# GD32C231 register map
File version: 1.0
CPU: CM23 r0p0, little endian, MPU, FPU, 4 interrupt priority bits
Registers are 32-bit, read-write, reset 0x0 unless marked. A register's access mark holds for its fields unless they carry their own. Offsets are from the block's base; [hi:lo] are bit positions.

## TIMER15 — General-level4-timers
Base 0x40014400
Same registers: TIMER16 0x40014800
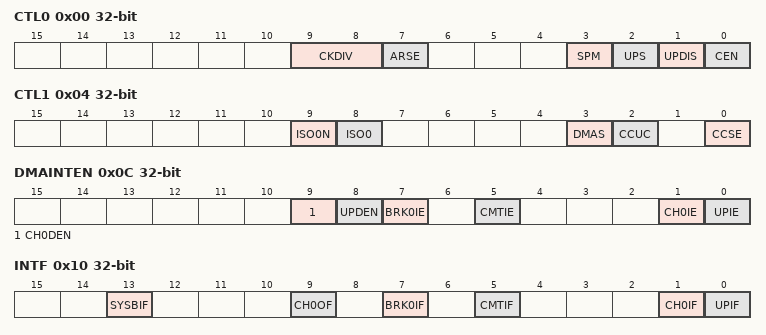
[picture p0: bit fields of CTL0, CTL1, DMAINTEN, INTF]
0x00 CTL0 — Control register 0
  [9:8] CKDIV — Clock division
  [7] ARSE — Auto-reload shadow enable
  [3] SPM — Single pulse mode.
  [2] UPS — Update source
  [1] UPDIS — Update disable.
  [0] CEN — Counter enable
0x04 CTL1 — Control register 1
  [9] ISO0N — Idle state of channel 0 complementary output
  [8] ISO0 — Idle state of channel 0 output
  [3] DMAS — DMA request source selection
  [2] CCUC — Commutation control shadow register update control
  [0] CCSE — Commutation control shadow enable
0x0C DMAINTEN — DMA and interrupt enable register
  [9] CH0DEN — Channel 0 capture/compare DMA request enable
  [8] UPDEN — Update DMA request enable
  [7] BRK0IE — Break interrupt 0 enable
  [5] CMTIE — Commutation interrupt enable
  [1] CH0IE — Channel 0 capture/compare interrupt enable
  [0] UPIE — Update interrupt enable
0x10 INTF — Interrupt flag register
  [13] SYSBIF — System source break interrupt flag
  [9] CH0OF — Channel 0 over capture flag
  [7] BRK0IF — Break 0 interrupt flag
  [5] CMTIF — Channel commutation interrupt flag
  [1] CH0IF — Channel 0 capture/compare interrupt flag
  [0] UPIF — Update interrupt flag
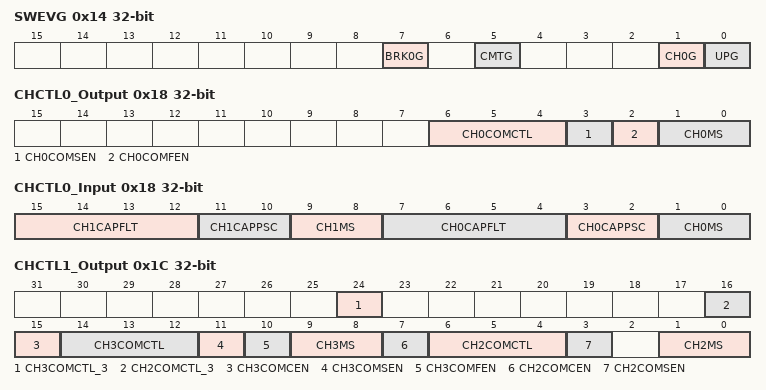
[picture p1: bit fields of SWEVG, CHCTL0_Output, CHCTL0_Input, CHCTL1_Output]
0x14 SWEVG wo — Software event generation register
  [7] BRK0G — Break 0 event generation
  [5] CMTG — Channel commutation event generation
  [1] CH0G — Channel 0 capture or compare event generation
  [0] UPG — Update event generation
0x18 CHCTL0_Output — channel control register 0 (output mode)
  [6:4] CH0COMCTL — Channel 0 compare output control
  [3] CH0COMSEN — Channel 0 compare output shadow enable
  [2] CH0COMFEN — Channel 0 output compare fast enable
  [1:0] CH0MS — Channel 0 I/O mode selection
0x18 CHCTL0_Input (alternate view of CHCTL0_Output) — channel control register 0 (input mode)
  [15:12] CH1CAPFLT — Channel 1 input capture filter control
  [11:10] CH1CAPPSC — Channel 1 input capture prescaler
  [9:8] CH1MS — Channel 1 mode selection
  [7:4] CH0CAPFLT — Channel 0 input capture filter control
  [3:2] CH0CAPPSC — Channel 0 input capture prescaler
  [1:0] CH0MS — Channel 0 mode selection
0x1C CHCTL1_Output — channel control register 1 (output mode)
  [24] CH3COMCTL_3 — Channel 3 compare output control
  [16] CH2COMCTL_3 — Channel 2 compare output control
  [15] CH3COMCEN — Channel 3 output compare clear enable
  [14:12] CH3COMCTL — Channel 3 compare output control
  [11] CH3COMSEN — Channel 3 output compare shadow enable
  [10] CH3COMFEN — Channel 3 output compare fast enable
  [9:8] CH3MS — Channel 3 mode selection
  [7] CH2COMCEN — Channel 2 output compare clear enable
  [6:4] CH2COMCTL — Channel 2 compare output control
  [3] CH2COMSEN — Channel 2 compare output shadow enable
  [1:0] CH2MS — Channel 2 I/O mode selection
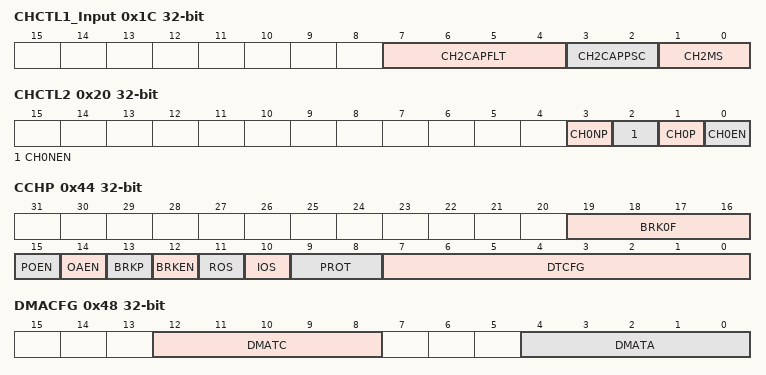
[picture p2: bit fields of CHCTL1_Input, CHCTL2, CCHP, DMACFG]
0x1C CHCTL1_Input (alternate view of CHCTL1_Output) — channel control register 1 (input mode)
  [7:4] CH2CAPFLT — Channel 2 input capture filter control
  [3:2] CH2CAPPSC — Channel 2 input capture prescaler
  [1:0] CH2MS — Channel 2 mode selection
0x20 CHCTL2 — Channel control register 2
  [3] CH0NP — Channel 0 complementary output polarity
  [2] CH0NEN — Channel 0 complementary output enable
  [1] CH0P — Channel 0 capture/compare function polarity
  [0] CH0EN — Channel 0 capture/compare function enable
0x24 CNT — Counter register
  [15:0] CNT — This bit-filed indicates the current counter value. Writing to this bit-filed can change the value of the counter.
0x28 PSC — Prescaler register
  [15:0] PSC — Prescaler value of the counter clock
0x2C CAR — Counter auto reload register
  [15:0] CARL — Counter auto reload value
0x30 CREP — Counter repetition register
  [7:0] CREP — Counter repetition value
0x34 CH0CV — Channel 0 capture/compare value register
  [15:0] CH0VAL — Capture or compare value of channel0
0x44 CCHP — Complementary channel protection register
  [19:16] BRK0F — BREAK0 input signal filter
  [15] POEN — Primary output enable
  [14] OAEN — Output automatic enable
  [13] BRKP — Break polarity
  [12] BRKEN — Break enable
  [11] ROS — Run mode 'off-state' enable
  [10] IOS — Idle mode 'off-state' enable
  [9:8] PROT — Complementary register protect control
  [7:0] DTCFG — Dead time configure
0x48 DMACFG — DMA configuration register
  [12:8] DMATC — DMA transfer count
  [4:0] DMATA — DMA transfer access start address
0x4C DMATB — DMA transfer buffer register
  [15:0] DMATB — DMA transfer buffer
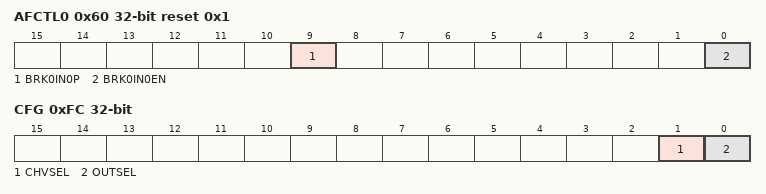
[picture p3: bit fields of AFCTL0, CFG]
0x60 AFCTL0 reset 0x1 — TIMERx alternate function control register 0
  [9] BRK0IN0P — BREAK0 BRKIN0 alternate function input polarity
  [0] BRK0IN0EN — BREAK0 BRKIN0 alternate function input enable
0x68 INSEL — input selection register
  [1:0] CI0_SEL — Channel 0 input selection
0xFC CFG — Configuration register
  [1] CHVSEL — Write CHxVAL register selection
  [0] OUTSEL — The output value selection
